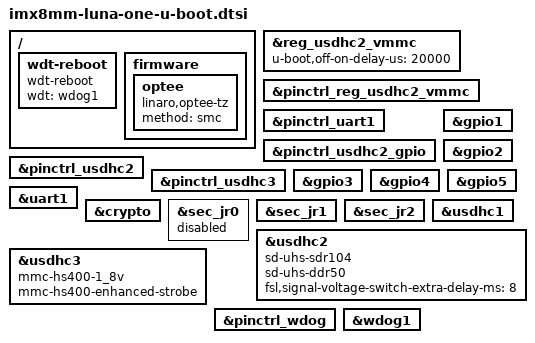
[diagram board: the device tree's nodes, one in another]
// SPDX-License-Identifier: GPL-2.0+
/*
 * Copyright 2019, 2021 NXP
 */

#include "imx8mm-u-boot.dtsi"

/ {
	wdt-reboot {
		compatible = "wdt-reboot";
		wdt = <&wdog1>;
		u-boot,dm-spl;
	};

	firmware {
		optee {
			compatible = "linaro,optee-tz";
			method = "smc";
		};
	};
};

&reg_usdhc2_vmmc {
	u-boot,off-on-delay-us = <20000>;
};

&pinctrl_reg_usdhc2_vmmc {
	u-boot,dm-spl;
};

&pinctrl_uart1 {
	u-boot,dm-spl;
};

&pinctrl_usdhc2_gpio {
	u-boot,dm-spl;
};

&pinctrl_usdhc2 {
	u-boot,dm-spl;
};

&pinctrl_usdhc3 {
	u-boot,dm-spl;
};

&gpio1 {
	u-boot,dm-spl;
};

&gpio2 {
	u-boot,dm-spl;
};

&gpio3 {
	u-boot,dm-spl;
};

&gpio4 {
	u-boot,dm-spl;
};

&gpio5 {
	u-boot,dm-spl;
};

&uart1 {
	u-boot,dm-spl;
};

&crypto {
	u-boot,dm-spl;
};

&sec_jr0 {
	u-boot,dm-spl;
	status = "disabled";
};

&sec_jr1 {
	u-boot,dm-spl;
};

&sec_jr2 {
	u-boot,dm-spl;
};

&usdhc1 {
	u-boot,dm-spl;
};

&usdhc2 {
	u-boot,dm-spl;
	sd-uhs-sdr104;
	sd-uhs-ddr50;
	fsl,signal-voltage-switch-extra-delay-ms = <8>;
};

&usdhc3 {
	u-boot,dm-spl;
	mmc-hs400-1_8v;
	mmc-hs400-enhanced-strobe;
};

&pinctrl_wdog {
	u-boot,dm-spl;
};


&wdog1 {
	u-boot,dm-spl;
};
